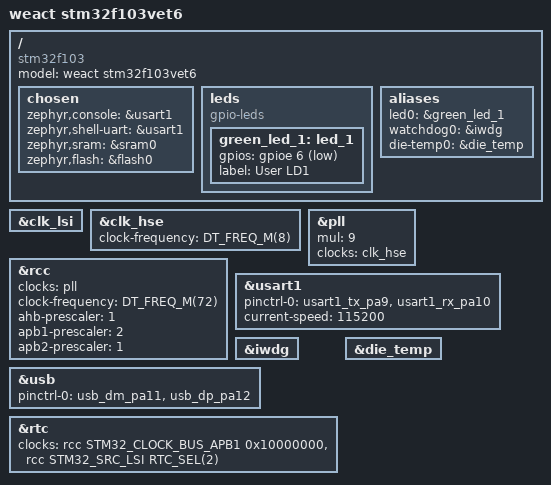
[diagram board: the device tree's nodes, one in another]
/*
 * SPDX-License-Identifier: Apache-2.0
 */

/dts-v1/;
#include <st/f1/stm32f103Xc.dtsi>
#include <st/f1/stm32f103r(c-d-e)tx-pinctrl.dtsi>

/ {
	model = "weact stm32f103vet6";
	compatible = "stm32f103";

	chosen {
		zephyr,console = &usart1;
		zephyr,shell-uart = &usart1;
		zephyr,sram = &sram0;
		zephyr,flash = &flash0;
	};

	leds {
		compatible = "gpio-leds";
		green_led_1: led_1 {
			gpios = <&gpioe 6 GPIO_ACTIVE_LOW>;
			label = "User LD1";
		};
	};

	aliases {
		led0 = &green_led_1;
		watchdog0 = &iwdg;
		die-temp0 = &die_temp;
	};
};

&clk_lsi {
	status = "okay";
};

&clk_hse {
	clock-frequency = <DT_FREQ_M(8)>;
	status = "okay";
};

&pll {
	mul = <9>;
	clocks = <&clk_hse>;
	status = "okay";
};

&rcc {
	clocks = <&pll>;
	clock-frequency = <DT_FREQ_M(72)>;
	ahb-prescaler = <1>;
	apb1-prescaler = <2>;
	apb2-prescaler = <1>;
	/* usbpre not set: USB clock = 72 / 1.5: 48MHz */
};

&usart1 {
	pinctrl-0 = <&usart1_tx_pa9 &usart1_rx_pa10>;
	pinctrl-names = "default";
	current-speed = <115200>;
	status = "okay";
};

&iwdg {
	status = "okay";
};

zephyr_udc0: &usb {
	pinctrl-0 = <&usb_dm_pa11 &usb_dp_pa12>;
	pinctrl-names = "default";
	status = "okay";
};

&rtc {
	clocks = <&rcc STM32_CLOCK_BUS_APB1 0x10000000>,
		 <&rcc STM32_SRC_LSI RTC_SEL(2)>;
	status = "okay";
};

&die_temp {
	status = "okay";
};
